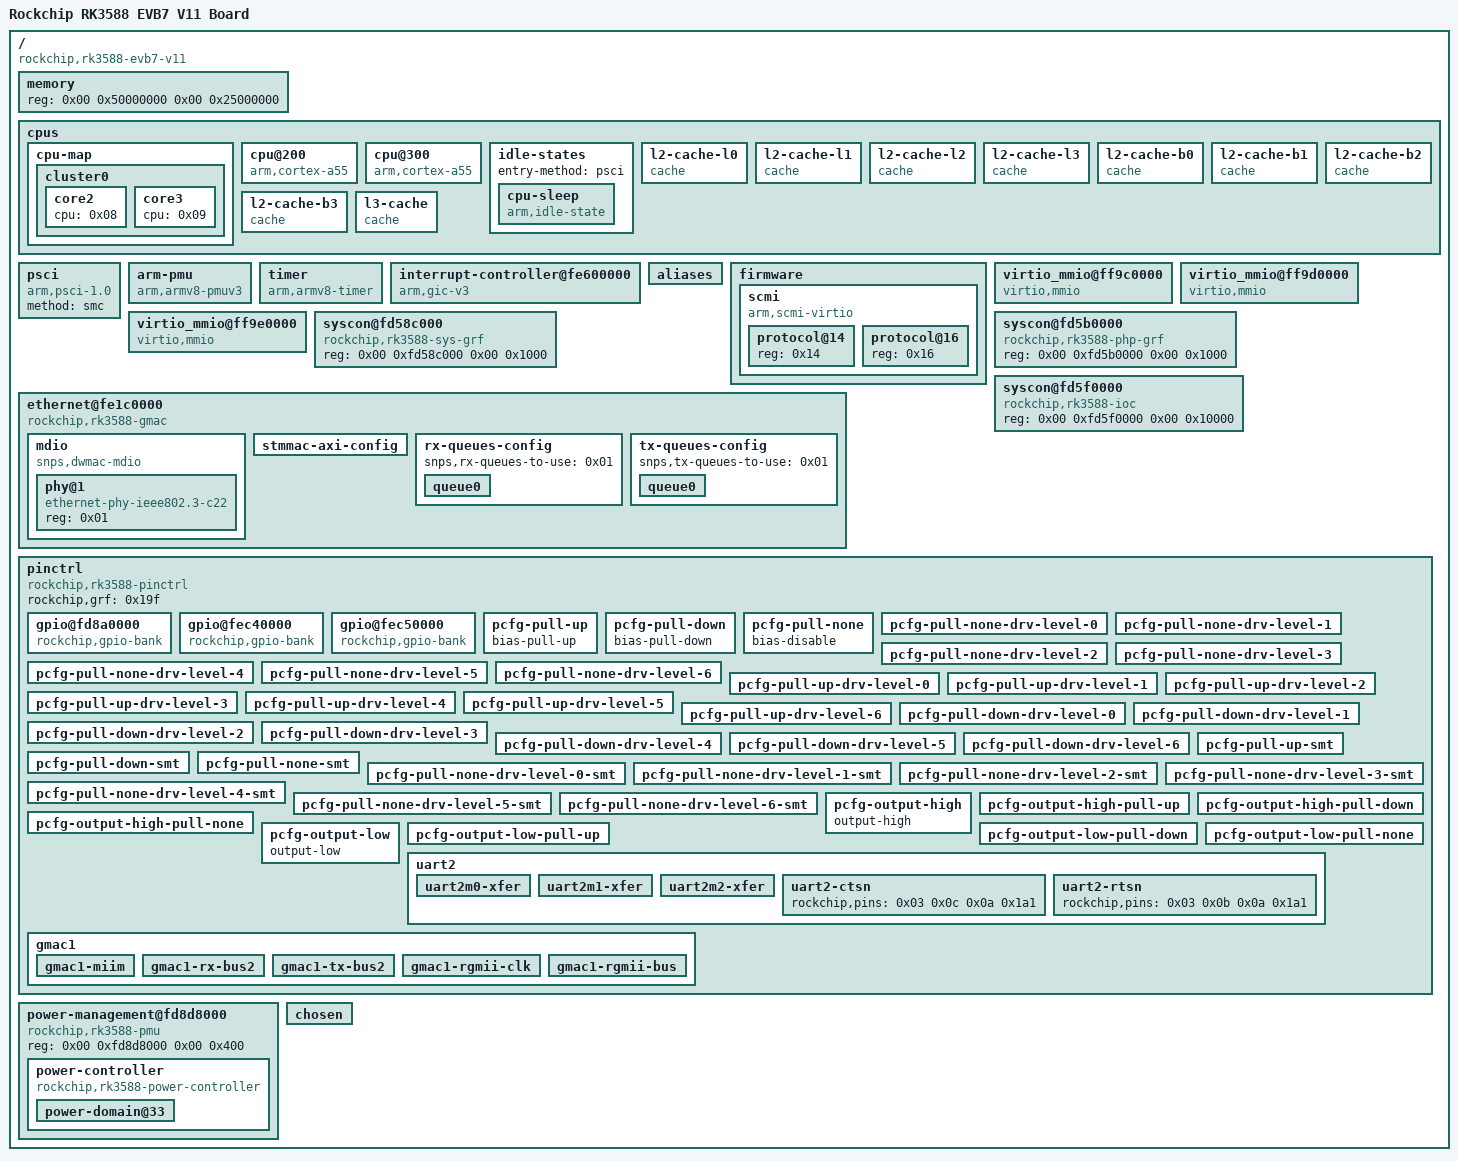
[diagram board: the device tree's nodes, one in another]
/dts-v1/;

/memreserve/	0x0000000008300000 0x0000000000047000;
/ {
	serial-number = "fe9d722c1f58159b";
	compatible = "rockchip,rk3588-evb7-v11\0rockchip,rk3588";
	interrupt-parent = <0x01>;
	#address-cells = <0x02>;
	#size-cells = <0x02>;
	model = "Rockchip RK3588 EVB7 V11 Board";

	memory {
		reg = <0x00 0x50000000 0x00 0x25000000>;
		device_type = "memory";
	};

	cpus {
		#address-cells = <0x01>;
		#size-cells = <0x00>;

		cpu-map {
			cluster0 {
				core2 {
					cpu = <0x08>;
				};
				core3 {
					cpu = <0x09>;
				};
			};
		};

		cpu@200 {
			device_type = "cpu";
			compatible = "arm,cortex-a55";
			reg = <0x200>;
			enable-method = "psci";
			capacity-dmips-mhz = <0x212>;
			clocks = <0x0e 0x00>;
			cpu-idle-states = <0x10>;
			i-cache-size = <0x8000>;
			i-cache-line-size = <0x40>;
			i-cache-sets = <0x80>;
			d-cache-size = <0x8000>;
			d-cache-line-size = <0x40>;
			d-cache-sets = <0x80>;
			next-level-cache = <0x14>;
			phandle = <0x08>;
		};

		cpu@300 {
			device_type = "cpu";
			compatible = "arm,cortex-a55";
			reg = <0x300>;
			enable-method = "psci";
			capacity-dmips-mhz = <0x212>;
			clocks = <0x0e 0x00>;
			cpu-idle-states = <0x10>;
			i-cache-size = <0x8000>;
			i-cache-line-size = <0x40>;
			i-cache-sets = <0x80>;
			d-cache-size = <0x8000>;
			d-cache-line-size = <0x40>;
			d-cache-sets = <0x80>;
			next-level-cache = <0x15>;
			phandle = <0x09>;
		};

		idle-states {
			entry-method = "psci";
			cpu-sleep {
				compatible = "arm,idle-state";
				local-timer-stop;
				arm,psci-suspend-param = <0x10000>;
				entry-latency-us = <0x64>;
				exit-latency-us = <0x78>;
				min-residency-us = <0x3e8>;
				phandle = <0x10>;
			};
		};

		l2-cache-l0 {
			compatible = "cache";
			cache-size = <0x20000>;
			cache-line-size = <0x40>;
			cache-sets = <0x200>;
			next-level-cache = <0x1e>;
			phandle = <0x11>;
		};

		l2-cache-l1 {
			compatible = "cache";
			cache-size = <0x20000>;
			cache-line-size = <0x40>;
			cache-sets = <0x200>;
			next-level-cache = <0x1e>;
			phandle = <0x13>;
		};

		l2-cache-l2 {
			compatible = "cache";
			cache-size = <0x20000>;
			cache-line-size = <0x40>;
			cache-sets = <0x200>;
			next-level-cache = <0x1e>;
			phandle = <0x14>;
		};

		l2-cache-l3 {
			compatible = "cache";
			cache-size = <0x20000>;
			cache-line-size = <0x40>;
			cache-sets = <0x200>;
			next-level-cache = <0x1e>;
			phandle = <0x15>;
		};

		l2-cache-b0 {
			compatible = "cache";
			cache-size = <0x80000>;
			cache-line-size = <0x40>;
			cache-sets = <0x400>;
			next-level-cache = <0x1e>;
			phandle = <0x17>;
		};

		l2-cache-b1 {
			compatible = "cache";
			cache-size = <0x80000>;
			cache-line-size = <0x40>;
			cache-sets = <0x400>;
			next-level-cache = <0x1e>;
			phandle = <0x19>;
		};

		l2-cache-b2 {
			compatible = "cache";
			cache-size = <0x80000>;
			cache-line-size = <0x40>;
			cache-sets = <0x400>;
			next-level-cache = <0x1e>;
			phandle = <0x1b>;
		};

		l2-cache-b3 {
			compatible = "cache";
			cache-size = <0x80000>;
			cache-line-size = <0x40>;
			cache-sets = <0x400>;
			next-level-cache = <0x1e>;
			phandle = <0x1d>;
		};

		l3-cache {
			compatible = "cache";
			cache-size = <0x300000>;
			cache-line-size = <0x40>;
			cache-sets = <0x1000>;
			phandle = <0x1e>;
		};
	};

	psci {
		compatible = "arm,psci-1.0";
		method = "smc";
	};

	arm-pmu {
		compatible = "arm,armv8-pmuv3";
		interrupts = <0x01 0x07 0x08>;
		interrupt-affinity = <0x06 0x07 0x08 0x09 0x0a 0x0b 0x0c 0x0d>;
		phandle = <0x220>;
	};

	timer {
		compatible = "arm,armv8-timer";
		interrupts = <0x01 0x0d 0xf04 0x01 0x0e 0xf04 0x01 0x0b 0xf04 0x01 0x0a 0xf04>;
	};

	interrupt-controller@fe600000 {
		compatible = "arm,gic-v3";
		#interrupt-cells = <0x03>;
		#address-cells = <0x02>;
		#size-cells = <0x02>;
		ranges;
		interrupt-controller;
		reg = <0x00 0xfe600000 0x00 0x10000 0x00 0xfe680000 0x00 0x100000>;
		interrupts = <0x01 0x09 0x04>;
		phandle = <0x01>;
	};

	
    aliases {
	};

	firmware {
		scmi {
			compatible = "arm,scmi-virtio";
			#address-cells = <0x01>;
			#size-cells = <0x00>;
			phandle = <0x1000>;

			protocol@14 {   // clock protocol
				reg = <0x14>;
				#clock-cells = <0x01>;
				phandle = <0x02>;
			};

			protocol@16 {    // reset protocol
				reg = <0x16>;
				#reset-cells = <0x01>;
				phandle = <0x1002>;  // 新的phandle值
			};
		};
	};

	// virtio scmi
	virtio_mmio@ff9c0000 {
		dma-coherent;
		interrupt-parent = <0x01>;    // reuse GIC
		interrupts = <0x0 0x2b 0x1>;  // new input id = 0x2b
		reg = <0x0 0xff9c0000 0x0 0x200>;
		compatible = "virtio,mmio";
	};

	// virtio blk
	virtio_mmio@ff9d0000 {
		dma-coherent;
		interrupt-parent = <0x01>;
		interrupts = <0x0 0x2e 0x1>;
		reg = <0x0 0xff9d0000 0x0 0x200>;
		compatible = "virtio,mmio";
	};

	// virtio serial
	virtio_mmio@ff9e0000 {
		dma-coherent;
		interrupt-parent = <0x01>;
		interrupts = <0x0 0x2c 0x1>;
		reg = <0x0 0xff9e0000 0x0 0x200>;
		compatible = "virtio,mmio";
	};


	// serial@feb50000 {
	// 	compatible = "rockchip,rk3588-uart\0snps,dw-apb-uart";
	// 	reg = <0x00 0xfeb50000 0x00 0x100>;
	// 	interrupts = <0x00 0x14d 0x04>;
	// 	//clocks = <0x02 0xbb 0x02 0xac>;
	// 	//clock-names = "baudclk\0apb_pclk";
	// 	reg-shift = <0x02>;
	// 	reg-io-width = <0x04>;
	// 	//pinctrl-names = "default";
	// 	//pinctrl-0 = <0x16d>;
	// 	status = "okay";
	// 	phandle = <0x2e2>;
	// };

	syscon@fd58c000 {
		compatible = "rockchip,rk3588-sys-grf\0syscon\0simple-mfd";
		reg = <0x00 0xfd58c000 0x00 0x1000>;
		phandle = <0xc3>;

		// rgb {
		// 	compatible = "rockchip,rk3588-rgb";
		// 	pinctrl-names = "default";
		// 	pinctrl-0 = <0x6e>;
		// 	status = "disabled";
		// 	phandle = <0x270>;

		// 	ports {
		// 		#address-cells = <0x01>;
		// 		#size-cells = <0x00>;

		// 		port@0 {
		// 			reg = <0x00>;
		// 			#address-cells = <0x01>;
		// 			#size-cells = <0x00>;

		// 			endpoint@2 {
		// 				reg = <0x02>;
		// 				remote-endpoint = <0x3a>;
		// 				status = "disabled";
		// 				phandle = <0xeb>;
		// 			};
		// 		};
		// 	};
		// };
	};

	syscon@fd5b0000 {
		compatible = "rockchip,rk3588-php-grf\0syscon";
		reg = <0x00 0xfd5b0000 0x00 0x1000>;
		phandle = <0x73>;
	};

	ethernet@fe1c0000 {
		local-mac-address = [0e f0 2e be b3 6c];
		compatible = "rockchip,rk3588-gmac", "snps,dwmac-4.20a";
		reg = <0x00 0xfe1c0000 0x00 0x10000>;
		interrupts = <0x00 0xea 0x04 0x00 0xe9 0x04>;
		interrupt-names = "macirq\0eth_wake_irq";
		rockchip,grf = <0xc3>;
		rockchip,php_grf = <0x73>;
		clocks = <0x02 0x144 0x02 0x145 0x02 0x168 0x02 0x16d 0x02 0x143>;
		clock-names = "stmmaceth\0clk_mac_ref\0pclk_mac\0aclk_mac\0ptp_ref";
		resets = <0x1002 0x138>;       // virt scmi reset id, original 0x20b
		reset-names = "stmmaceth";
		power-domains = <0x5d 0x21>;
		snps,mixed-burst;
		snps,tso;
		snps,axi-config = <0x110>;
		snps,mtl-rx-config = <0x111>;
		snps,mtl-tx-config = <0x112>;
		status = "okay";
		phy-mode = "rgmii-rxid";
		clock_in_out = "output";
		snps,reset-gpio = <0x113 0x0f 0x01>;
		snps,reset-active-low;
		snps,reset-delays-us = <0x00 0x4e20 0x186a0>;
		pinctrl-names = "default";
		pinctrl-0 = <0x114 0x115 0x116 0x117 0x118>;
		tx_delay = <0x43>;
		phy-handle = <0x119>;
		phandle = <0x10f>;

		mdio {
			compatible = "snps,dwmac-mdio";
			#address-cells = <0x01>;
			#size-cells = <0x00>;
			phandle = <0x2a4>;

			phy@1 {
				compatible = "ethernet-phy-ieee802.3-c22";
				reg = <0x01>;
				phandle = <0x119>;
			};
		};

		stmmac-axi-config {
			snps,wr_osr_lmt = <0x04>;
			snps,rd_osr_lmt = <0x08>;
			snps,blen = <0x00 0x00 0x00 0x00 0x10 0x08 0x04>;
			phandle = <0x110>;
		};

		rx-queues-config {
			snps,rx-queues-to-use = <0x01>;
			phandle = <0x111>;

			queue0 {
			};
		};

		tx-queues-config {
			snps,tx-queues-to-use = <0x01>;
			phandle = <0x112>;

			queue0 {
			};
		};
	};

	syscon@fd5f0000 {
		compatible = "rockchip,rk3588-ioc\0syscon";
		reg = <0x00 0xfd5f0000 0x00 0x10000>;
		phandle = <0x19f>;
	};

	pinctrl {
		compatible = "rockchip,rk3588-pinctrl";
		rockchip,grf = <0x19f>;
		#address-cells = <0x02>;
		#size-cells = <0x02>;
		ranges;
		phandle = <0x1a0>;

		gpio@fd8a0000 {
			compatible = "rockchip,gpio-bank";
			reg = <0x00 0xfd8a0000 0x00 0x100>;
			interrupts = <0x00 0x115 0x04>;
			clocks = <0x02 0x284 0x02 0x285>;
			gpio-controller;
			#gpio-cells = <0x02>;
			gpio-ranges = <0x1a0 0x00 0x00 0x20>;
			interrupt-controller;
			#interrupt-cells = <0x02>;
			phandle = <0xf2>;
		};

		gpio@fec40000 {
			compatible = "rockchip,gpio-bank";
			reg = <0x00 0xfec40000 0x00 0x100>;
			interrupts = <0x00 0x118 0x04>;
			clocks = <0x02 0x81 0x02 0x82>;
			gpio-controller;
			#gpio-cells = <0x02>;
			gpio-ranges = <0x1a0 0x00 0x60 0x20>;
			interrupt-controller;
			#interrupt-cells = <0x02>;
			phandle = <0x113>;
		};

		gpio@fec50000 {
			compatible = "rockchip,gpio-bank";
			reg = <0x00 0xfec50000 0x00 0x100>;
			interrupts = <0x00 0x119 0x04>;
			clocks = <0x02 0x83 0x02 0x84>;
			gpio-controller;
			#gpio-cells = <0x02>;
			gpio-ranges = <0x1a0 0x00 0x80 0x20>;
			interrupt-controller;
			#interrupt-cells = <0x02>;
			phandle = <0x104>;
		};

		pcfg-pull-up {
			bias-pull-up;
			phandle = <0x1a6>;
		};

		pcfg-pull-down {
			bias-pull-down;
			phandle = <0x1aa>;
		};

		pcfg-pull-none {
			bias-disable;
			phandle = <0x1a1>;
		};

		pcfg-pull-none-drv-level-0 {
			bias-disable;
			drive-strength = <0x00>;
			phandle = <0x303>;
		};

		pcfg-pull-none-drv-level-1 {
			bias-disable;
			drive-strength = <0x01>;
			phandle = <0x304>;
		};

		pcfg-pull-none-drv-level-2 {
			bias-disable;
			drive-strength = <0x02>;
			phandle = <0x1a9>;
		};

		pcfg-pull-none-drv-level-3 {
			bias-disable;
			drive-strength = <0x03>;
			phandle = <0x305>;
		};

		pcfg-pull-none-drv-level-4 {
			bias-disable;
			drive-strength = <0x04>;
			phandle = <0x306>;
		};

		pcfg-pull-none-drv-level-5 {
			bias-disable;
			drive-strength = <0x05>;
			phandle = <0x307>;
		};

		pcfg-pull-none-drv-level-6 {
			bias-disable;
			drive-strength = <0x06>;
			phandle = <0x308>;
		};

		pcfg-pull-up-drv-level-0 {
			bias-pull-up;
			drive-strength = <0x00>;
			phandle = <0x309>;
		};

		pcfg-pull-up-drv-level-1 {
			bias-pull-up;
			drive-strength = <0x01>;
			phandle = <0x1a8>;
		};

		pcfg-pull-up-drv-level-2 {
			bias-pull-up;
			drive-strength = <0x02>;
			phandle = <0x1a2>;
		};

		pcfg-pull-up-drv-level-3 {
			bias-pull-up;
			drive-strength = <0x03>;
			phandle = <0x30a>;
		};

		pcfg-pull-up-drv-level-4 {
			bias-pull-up;
			drive-strength = <0x04>;
			phandle = <0x30b>;
		};

		pcfg-pull-up-drv-level-5 {
			bias-pull-up;
			drive-strength = <0x05>;
			phandle = <0x30c>;
		};

		pcfg-pull-up-drv-level-6 {
			bias-pull-up;
			drive-strength = <0x06>;
			phandle = <0x1a7>;
		};

		pcfg-pull-down-drv-level-0 {
			bias-pull-down;
			drive-strength = <0x00>;
			phandle = <0x30d>;
		};

		pcfg-pull-down-drv-level-1 {
			bias-pull-down;
			drive-strength = <0x01>;
			phandle = <0x30e>;
		};

		pcfg-pull-down-drv-level-2 {
			bias-pull-down;
			drive-strength = <0x02>;
			phandle = <0x30f>;
		};

		pcfg-pull-down-drv-level-3 {
			bias-pull-down;
			drive-strength = <0x03>;
			phandle = <0x310>;
		};

		pcfg-pull-down-drv-level-4 {
			bias-pull-down;
			drive-strength = <0x04>;
			phandle = <0x311>;
		};

		pcfg-pull-down-drv-level-5 {
			bias-pull-down;
			drive-strength = <0x05>;
			phandle = <0x312>;
		};

		pcfg-pull-down-drv-level-6 {
			bias-pull-down;
			drive-strength = <0x06>;
			phandle = <0x313>;
		};

		pcfg-pull-up-smt {
			bias-pull-up;
			input-schmitt-enable;
			phandle = <0x314>;
		};

		pcfg-pull-down-smt {
			bias-pull-down;
			input-schmitt-enable;
			phandle = <0x315>;
		};

		pcfg-pull-none-smt {
			bias-disable;
			input-schmitt-enable;
			phandle = <0x1a5>;
		};

		pcfg-pull-none-drv-level-0-smt {
			bias-disable;
			drive-strength = <0x00>;
			input-schmitt-enable;
			phandle = <0x316>;
		};

		pcfg-pull-none-drv-level-1-smt {
			bias-disable;
			drive-strength = <0x01>;
			input-schmitt-enable;
			phandle = <0x1a4>;
		};

		pcfg-pull-none-drv-level-2-smt {
			bias-disable;
			drive-strength = <0x02>;
			input-schmitt-enable;
			phandle = <0x317>;
		};

		pcfg-pull-none-drv-level-3-smt {
			bias-disable;
			drive-strength = <0x03>;
			input-schmitt-enable;
			phandle = <0x318>;
		};

		pcfg-pull-none-drv-level-4-smt {
			bias-disable;
			drive-strength = <0x04>;
			input-schmitt-enable;
			phandle = <0x319>;
		};

		pcfg-pull-none-drv-level-5-smt {
			bias-disable;
			drive-strength = <0x05>;
			input-schmitt-enable;
			phandle = <0x1a3>;
		};

		pcfg-pull-none-drv-level-6-smt {
			bias-disable;
			drive-strength = <0x06>;
			input-schmitt-enable;
			phandle = <0x31a>;
		};

		pcfg-output-high {
			output-high;
			phandle = <0x31b>;
		};

		pcfg-output-high-pull-up {
			output-high;
			bias-pull-up;
			phandle = <0x31c>;
		};

		pcfg-output-high-pull-down {
			output-high;
			bias-pull-down;
			phandle = <0x31d>;
		};

		pcfg-output-high-pull-none {
			output-high;
			bias-disable;
			phandle = <0x31e>;
		};

		pcfg-output-low {
			output-low;
			phandle = <0x1ab>;
		};

		pcfg-output-low-pull-up {
			output-low;
			bias-pull-up;
			phandle = <0x31f>;
		};

		pcfg-output-low-pull-down {
			output-low;
			bias-pull-down;
			phandle = <0x320>;
		};

		pcfg-output-low-pull-none {
			output-low;
			bias-disable;
			phandle = <0x321>;
		};

		uart2 {

			uart2m0-xfer {
				rockchip,pins = <0x00 0x0e 0x0a 0x1a6 0x00 0x0d 0x0a 0x1a6>;
				phandle = <0x202>;
			};

			uart2m1-xfer {
				rockchip,pins = <0x04 0x19 0x0a 0x1a6 0x04 0x18 0x0a 0x1a6>;
				phandle = <0x16d>;
			};

			uart2m2-xfer {
				rockchip,pins = <0x03 0x0a 0x0a 0x1a6 0x03 0x09 0x0a 0x1a6>;
				phandle = <0x438>;
			};

			uart2-ctsn {
				rockchip,pins = <0x03 0x0c 0x0a 0x1a1>;
				phandle = <0x439>;
			};

			uart2-rtsn {
				rockchip,pins = <0x03 0x0b 0x0a 0x1a1>;
				phandle = <0x43a>;
			};
		};

		gmac1 {

			gmac1-miim {
				rockchip,pins = <0x03 0x12 0x01 0x1a1 0x03 0x13 0x01 0x1a1>;
				phandle = <0x114>;
			};

			gmac1-rx-bus2 {
				rockchip,pins = <0x03 0x07 0x01 0x1a1 0x03 0x08 0x01 0x1a1 0x03 0x09 0x01 0x1a1>;
				phandle = <0x116>;
			};

			gmac1-tx-bus2 {
				rockchip,pins = <0x03 0x0b 0x01 0x1a1 0x03 0x0c 0x01 0x1a1 0x03 0x0d 0x01 0x1a1>;
				phandle = <0x115>;
			};

			gmac1-rgmii-clk {
				rockchip,pins = <0x03 0x05 0x01 0x1a1 0x03 0x04 0x01 0x1a1>;
				phandle = <0x117>;
			};

			gmac1-rgmii-bus {
				rockchip,pins = <0x03 0x02 0x01 0x1a1 0x03 0x03 0x01 0x1a1 0x03 0x00 0x01 0x1a1 0x03 0x01 0x01 0x1a1>;
				phandle = <0x118>;
			};
		};
	};

	power-management@fd8d8000 {
		compatible = "rockchip,rk3588-pmu\0syscon\0simple-mfd";
		reg = <0x00 0xfd8d8000 0x00 0x400>;
		phandle = <0xd4>;

		power-controller {
			compatible = "rockchip,rk3588-power-controller";
			#power-domain-cells = <0x01>;
			#address-cells = <0x01>;
			#size-cells = <0x00>;
			status = "okay";
			phandle = <0x5d>;

			power-domain@33 {
				reg = <0x21>;
				clocks = <0x02 0x166 0x02 0x169 0x02 0x16a>;
			};
		};
	};

    chosen {
		bootargs = "earlycon=virtio,mmio,0xff9e0000 console=hvc0 root=/dev/vda rootwait rw loglevel=7";
		// bootargs = "earlycon=uart8250,mmio32,0xfeb50000 console=hvc0 root=/dev/vda rootwait rw";
		stdout-path = "/virtio_mmio@0xff9e0000";
	};
};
